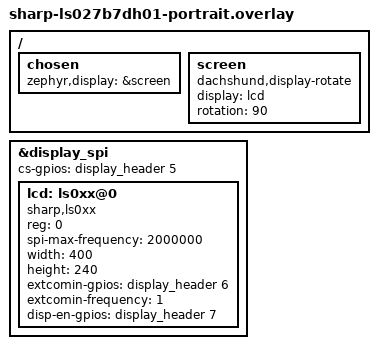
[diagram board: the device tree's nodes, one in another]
/*
 * 2.7" Sharp memory LCD (LS027B7DH01, 400x240) standing on end, as in the
 * case's sidebar: 240 x 400 pixels in portrait, turned in software
 * (dachshund,display-rotate). The panel's tail plugs straight into the
 * mainboard's J4, and the mainboard's U5 makes its 5 V supply.
 *
 * display_header keeps the old e-paper header's numbering (3 DIN ... 8 BUSY)
 * so the MCU pins stay the same: SI = 3 (DIN), SCLK = 4 (CLK),
 * SCS = 5 (CS, active high), EXTCOMIN = 6 (DC), DISP = 7 (RST). 8 (BUSY) is
 * the boost enable, pulled up on the board and left alone here.
 * If the text is upside down, set rotation to 270.
 */

/ {
	chosen {
		zephyr,display = &screen;
	};

	screen: screen {
		compatible = "dachshund,display-rotate";
		display = <&lcd>;
		rotation = <90>;
	};
};

&display_spi {
	status = "okay";
	cs-gpios = <&display_header 5 GPIO_ACTIVE_HIGH>;

	lcd: ls0xx@0 {
		compatible = "sharp,ls0xx";
		reg = <0>;
		/* 2 MHz is the panel's maximum: a full frame takes about 50 ms. */
		spi-max-frequency = <2000000>;
		width = <400>;
		height = <240>;
		extcomin-gpios = <&display_header 6 GPIO_ACTIVE_HIGH>;
		/* VCOM inversion, which the panel needs at 1 Hz or more. */
		extcomin-frequency = <1>;
		disp-en-gpios = <&display_header 7 GPIO_ACTIVE_HIGH>;
	};
};
